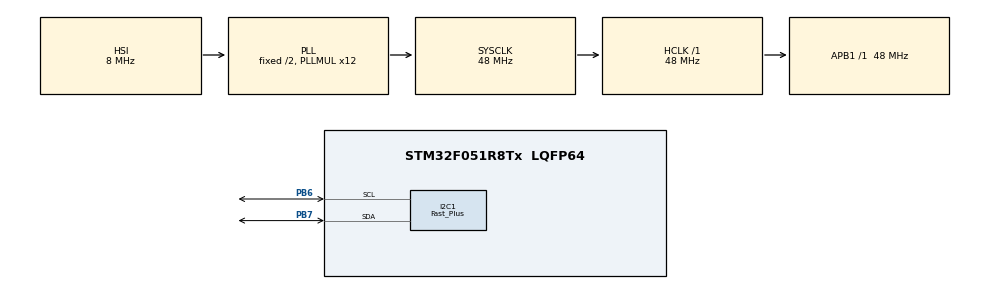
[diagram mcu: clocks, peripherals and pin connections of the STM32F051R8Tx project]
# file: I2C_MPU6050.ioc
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I2C1.I2C_Coeff_DF=5
I2C1.I2C_Speed_Mode=I2C_Fast_Plus
I2C1.Timing=0x00000000
Mcu.Family=STM32F0
Mcu.Name=STM32F051R8Tx
Mcu.Package=LQFP64
PA13.Mode=Serial_Wire
PA13.Signal=SYS_SWDIO
PA14.Mode=Serial_Wire
PA14.Signal=SYS_SWCLK
PB6.GPIO_Pu=GPIO_PULLUP
PB6.Mode=I2C
PB6.Signal=I2C1_SCL
PB7.GPIO_Pu=GPIO_PULLUP
PB7.Mode=I2C
PB7.Signal=I2C1_SDA
PF0-OSC_IN.Mode=HSE-External-Oscillator
PF0-OSC_IN.Signal=RCC_OSC_IN
PF1-OSC_OUT.Mode=HSE-External-Oscillator
PF1-OSC_OUT.Signal=RCC_OSC_OUT
ProjectManager.HeapSize=0x200
ProjectManager.StackSize=0x400
ProjectManager.TargetToolchain=STM32CubeIDE
RCC.AHBFreq_Value=48000000
RCC.APB1Freq_Value=48000000
RCC.APB1TimFreq_Value=48000000
RCC.HCLKFreq_Value=48000000
RCC.PLLMUL=RCC_PLL_MUL12
RCC.SYSCLKFreq_VALUE=48000000
RCC.SYSCLKSource=RCC_SYSCLKSOURCE_PLLCLK
board=custom

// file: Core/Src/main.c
/* USER CODE BEGIN Header */
/**
  ******************************************************************************
  * @file           : main.c
  * @brief          : Main program body
  ******************************************************************************
  * @attention
  *
  * Copyright (c) 2022 STMicroelectronics.
  * All rights reserved.
  *
  * This software is licensed under terms that can be found in the LICENSE file
  * in the root directory of this software component.
  * If no LICENSE file comes with this software, it is provided AS-IS.
  *
  ******************************************************************************
  */
/* USER CODE END Header */
#include "main.h"

/* USER CODE BEGIN Includes */
#include <math.h>

/* USER CODE END Includes */

 I2C_HandleTypeDef hi2c1;

/* USER CODE BEGIN PV */
HAL_StatusTypeDef result;

/* USER CODE END PV */

void SystemClock_Config(void);
static void MX_GPIO_Init(void);
static void MX_I2C1_Init(void);
void MPU6050_Init(void);
void MPU6050_Read_Accel(void);
void MPU6050_Read_Gyro(void);

/* USER CODE BEGIN 0 */

#define MPU6050_ADDR 0xD0

#define  SMPLRT_DIV_REG 0x19
#define GYRO_CONFIG_REG 0x1B
#define ACCEL_CONFIG_REG 0x1C
#define ACCEL_XOUT_H_REG 0x3B
#define TEMP_OUT_H_REG 0x41
#define GYRO_XOUT_H_REG 0x43
#define PWR_MGMT_1_REG 0x6B
#define WHO_AM_I_REG 0x75

int16_t GYRO_X = 0;
int16_t GYRO_Y = 0;
int16_t GYRO_Z = 0;

int16_t ACCEL_X = 0;
int16_t ACCEL_Y = 0;
int16_t ACCEL_Z = 0;

float GX,GY,GZ,AX,AY,AZ;
float mean_GX[100], mean_GY[100], mean_GZ[100];
float sumx=0, sumy=0, sumz=0;
float avg_GX=0, avg_GY=0, avg_GZ=0;
int z = 0;
int i;
int j;

/* USER CODE END 0 */

int main(void)
{

  /* MCU Configuration--------------------------------------------------------*/

  /* Reset of all peripherals, Initializes the Flash interface and the Systick. */
  HAL_Init();

  /* Configure the system clock */
  SystemClock_Config();

  /* Initialize all configured peripherals */
  MX_GPIO_Init();
  MX_I2C1_Init();
  /* USER CODE BEGIN 2 */
  MPU6050_Init();
//result = HAL_I2C_IsDeviceReady(&hi2c1, MPU6050_ADDR, 6, 1000);
  /* USER CODE END 2 */

  /* Infinite loop */
  while (1)
  {

    /* USER CODE BEGIN 3 */
	  MPU6050_Read_Gyro();
	  MPU6050_Read_Accel();

  }
  /* USER CODE END 3 */
}

void SystemClock_Config(void)
{
  RCC_OscInitTypeDef RCC_OscInitStruct = {0};
  RCC_ClkInitTypeDef RCC_ClkInitStruct = {0};
  RCC_PeriphCLKInitTypeDef PeriphClkInit = {0};

  /** Initializes the RCC Oscillators according to the specified parameters
  * in the RCC_OscInitTypeDef structure.
  */
  RCC_OscInitStruct.OscillatorType = RCC_OSCILLATORTYPE_HSI;
  RCC_OscInitStruct.HSIState = RCC_HSI_ON;
  RCC_OscInitStruct.HSICalibrationValue = RCC_HSICALIBRATION_DEFAULT;
  RCC_OscInitStruct.PLL.PLLState = RCC_PLL_ON;
  RCC_OscInitStruct.PLL.PLLSource = RCC_PLLSOURCE_HSI;
  RCC_OscInitStruct.PLL.PLLMUL = RCC_PLL_MUL12;
  RCC_OscInitStruct.PLL.PREDIV = RCC_PREDIV_DIV1;
  if (HAL_RCC_OscConfig(&RCC_OscInitStruct) != HAL_OK)
  {
    Error_Handler();
  }

  /** Initializes the CPU, AHB and APB buses clocks
  */
  RCC_ClkInitStruct.ClockType = RCC_CLOCKTYPE_HCLK|RCC_CLOCKTYPE_SYSCLK
                              |RCC_CLOCKTYPE_PCLK1;
  RCC_ClkInitStruct.SYSCLKSource = RCC_SYSCLKSOURCE_PLLCLK;
  RCC_ClkInitStruct.AHBCLKDivider = RCC_SYSCLK_DIV1;
  RCC_ClkInitStruct.APB1CLKDivider = RCC_HCLK_DIV1;

  if (HAL_RCC_ClockConfig(&RCC_ClkInitStruct, FLASH_LATENCY_1) != HAL_OK)
  {
    Error_Handler();
  }
  PeriphClkInit.PeriphClockSelection = RCC_PERIPHCLK_I2C1;
  PeriphClkInit.I2c1ClockSelection = RCC_I2C1CLKSOURCE_HSI;
  if (HAL_RCCEx_PeriphCLKConfig(&PeriphClkInit) != HAL_OK)
  {
    Error_Handler();
  }
}

static void MX_I2C1_Init(void)
{

  hi2c1.Instance = I2C1;
  hi2c1.Init.Timing = 0x00000000;
  hi2c1.Init.OwnAddress1 = 0;
  hi2c1.Init.AddressingMode = I2C_ADDRESSINGMODE_7BIT;
  hi2c1.Init.DualAddressMode = I2C_DUALADDRESS_DISABLE;
  hi2c1.Init.OwnAddress2 = 0;
  hi2c1.Init.OwnAddress2Masks = I2C_OA2_NOMASK;
  hi2c1.Init.GeneralCallMode = I2C_GENERALCALL_DISABLE;
  hi2c1.Init.NoStretchMode = I2C_NOSTRETCH_DISABLE;
  if (HAL_I2C_Init(&hi2c1) != HAL_OK)
  {
    Error_Handler();
  }

  /** Configure Analogue filter
  */
  if (HAL_I2CEx_ConfigAnalogFilter(&hi2c1, I2C_ANALOGFILTER_ENABLE) != HAL_OK)
  {
    Error_Handler();
  }

  /** Configure Digital filter
  */
  if (HAL_I2CEx_ConfigDigitalFilter(&hi2c1, 5) != HAL_OK)
  {
    Error_Handler();
  }

  /** I2C Fast mode Plus enable
  */
  __HAL_SYSCFG_FASTMODEPLUS_ENABLE(I2C_FASTMODEPLUS_I2C1);

}

static void MX_GPIO_Init(void)
{

  /* GPIO Ports Clock Enable */
  __HAL_RCC_GPIOF_CLK_ENABLE();
  __HAL_RCC_GPIOA_CLK_ENABLE();
  __HAL_RCC_GPIOB_CLK_ENABLE();

}

/* USER CODE BEGIN 4 */

void MPU6050_Init(void)
{

	uint8_t check[1];
	uint8_t Data[1];

	HAL_I2C_Mem_Read(&hi2c1, MPU6050_ADDR, WHO_AM_I_REG, 1, &check[0], 1, 1000);

	result = HAL_I2C_Mem_Read(&hi2c1, MPU6050_ADDR, WHO_AM_I_REG, 1, &check[0], 1, 1000);

	z = check[0];

	if (check[0] == 104){

		Data[0] = 0x00;
		HAL_I2C_Mem_Write(&hi2c1, MPU6050_ADDR, PWR_MGMT_1_REG, 1, &Data[0], 1, 1000);

		Data[0] = 0x07;
		HAL_I2C_Mem_Write(&hi2c1, MPU6050_ADDR, SMPLRT_DIV_REG, 1, &Data[0], 1, 1000);

		Data[0] = 0x00;
		HAL_I2C_Mem_Write(&hi2c1, MPU6050_ADDR, GYRO_CONFIG_REG, 1, &Data[0], 1, 1000);

		Data[0] = 0x00;
		HAL_I2C_Mem_Write(&hi2c1, MPU6050_ADDR, ACCEL_CONFIG_REG, 1, &Data[0], 1, 1000);
	}

}

void MPU6050_Read_Accel(void){
	uint8_t Rec_Data[6];

	  Rec_Data[0] = 0X3B;
	  HAL_I2C_Master_Transmit(&hi2c1, MPU6050_ADDR, Rec_Data, 1, 5000);
	  HAL_I2C_Master_Receive(&hi2c1, MPU6050_ADDR, Rec_Data, 6, 5000);

	ACCEL_X = (int16_t)(Rec_Data[0] << 8 | Rec_Data[1]);
	ACCEL_Y = (int16_t)(Rec_Data[2] << 8 | Rec_Data[3]);
	ACCEL_Z = (int16_t)(Rec_Data[4] << 8 | Rec_Data[5]);

	AX = ACCEL_X/16384.0;
	AY = ACCEL_Y/16384.0;
	AZ = ACCEL_Z/16384.0;

}

void MPU6050_Read_Gyro(void){
	  uint8_t Rec_Data2[6];

	  Rec_Data2[0]=0x43;
	  HAL_I2C_Master_Transmit(&hi2c1, MPU6050_ADDR, Rec_Data2, 1, 5000);
	  HAL_I2C_Master_Receive(&hi2c1, MPU6050_ADDR, Rec_Data2, 6, 5000);

	  GYRO_X = (int16_t)(Rec_Data2[0] << 8 | Rec_Data2[1]);
	  GX = GYRO_X/131.1;
	  mean_GX[i] = GX;
	  i++;

	  GYRO_Y = (int16_t)(Rec_Data2[2] << 8 | Rec_Data2[3]);
	  GY = GYRO_Y/131.1;
	  mean_GY[i] = GY;

	  GYRO_Z = (int16_t)(Rec_Data2[4] << 8 | Rec_Data2[5]);
	  GZ = GYRO_Z/131.1;
	  mean_GZ[i] = GZ;

	  if (i >= 100)
	  {
		  for(j=0;j<100;j++)
		  {
		  sumx = sumx + mean_GX[j];
		  sumy = sumy + mean_GY[j];
		  sumz = sumz + mean_GZ[j];
		  }
		  avg_GX = sumx / 100;
		  avg_GY = sumy / 100;
		  avg_GZ = sumz / 100;

		  i=0;
		  sumx = 0;
		  sumy = 0;
		  sumz = 0;
	  }

}

/* USER CODE END 4 */

void Error_Handler(void)
{
  __disable_irq();
  while (1)
  {
  }
}
